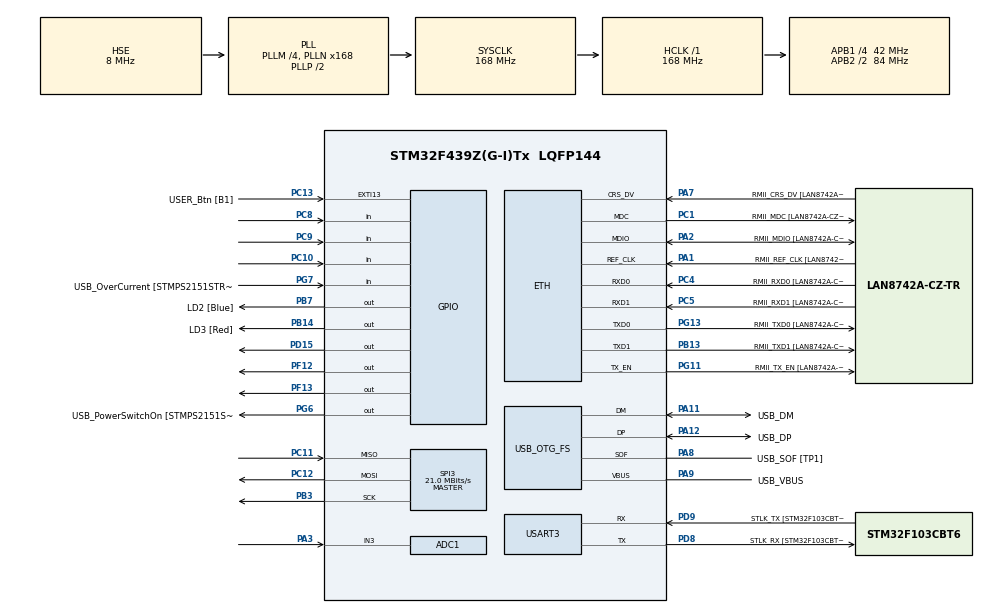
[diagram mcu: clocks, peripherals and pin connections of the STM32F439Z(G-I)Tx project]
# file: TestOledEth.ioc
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ADC1.Channel-1\#ChannelRegularConversion=ADC_CHANNEL_3
ADC1.NbrOfConversionFlag=1
ADC1.Rank-1\#ChannelRegularConversion=1
ADC1.SamplingTime-1\#ChannelRegularConversion=ADC_SAMPLETIME_3CYCLES
ADC1.master=1
ETH.MediaInterface=HAL_ETH_RMII_MODE
ETH.PHY_Name=LAN8742A_PHY_ADDRESS
ETH.PHY_Value=0
ETH.PhyAddress=0
FREERTOS.Tasks01=defaultTask,24,128,StartDefaultTask,Default,NULL,Dynamic,NULL,NULL
LWIP.BSP.number=1
LWIP.Version=v2.1.2_Cube
LWIP0.BSP.STBoard=false
LWIP0.BSP.api=BSP_COMPONENT_DRIVER
LWIP0.BSP.component=LAN8742
LWIP0.BSP.instance=LAN8742
LWIP0.BSP.name=Driver_PHY
LWIP0.BSP.semaphore=S_LAN8742
LWIP0.BSP.solution=LAN8742
Mcu.Family=STM32F4
Mcu.Name=STM32F439Z(G-I)Tx
Mcu.Package=LQFP144
NVIC.ETH_IRQn=true\:5\:0\:false\:false\:true\:true\:false\:true\:true
NVIC.PriorityGroup=NVIC_PRIORITYGROUP_4
NVIC.TIM6_DAC_IRQn=true\:15\:0\:false\:false\:true\:false\:false\:true\:true
NVIC.TimeBase=TIM6_DAC_IRQn
NVIC.TimeBaseIP=TIM6
PA1.GPIO_Label=RMII_REF_CLK [LAN8742A-CZ-TR_REFCLK0]
PA1.Mode=RMII
PA1.Signal=ETH_REF_CLK
PA10.GPIO_Label=USB_ID
PA10.Signal=USB_OTG_FS_ID
PA11.GPIO_Label=USB_DM
PA11.Mode=Device_Only
PA11.Signal=USB_OTG_FS_DM
PA12.GPIO_Label=USB_DP
PA12.Mode=Device_Only
PA12.Signal=USB_OTG_FS_DP
PA13.GPIO_Label=TMS
PA13.Mode=Serial_Wire
PA13.Signal=SYS_JTMS-SWDIO
PA14.GPIO_Label=TCK
PA14.Mode=Serial_Wire
PA14.Signal=SYS_JTCK-SWCLK
PA2.GPIO_Label=RMII_MDIO [LAN8742A-CZ-TR_MDIO]
PA2.Mode=RMII
PA2.Signal=ETH_MDIO
PA3.Signal=ADCx_IN3
PA7.GPIO_Label=RMII_CRS_DV [LAN8742A-CZ-TR_CRS_DV]
PA7.Mode=RMII
PA7.Signal=ETH_CRS_DV
PA8.GPIO_Label=USB_SOF [TP1]
PA8.Mode=Activate_SOF_FS
PA8.Signal=USB_OTG_FS_SOF
PA9.GPIO_Label=USB_VBUS
PA9.Mode=Activate_VBUS
PA9.Signal=USB_OTG_FS_VBUS
PB13.GPIO_Label=RMII_TXD1 [LAN8742A-CZ-TR_TXD1]
PB13.Mode=RMII
PB13.Signal=ETH_TXD1
PB14.GPIO_Label=LD3 [Red]
PB14.Signal=GPIO_Output
PB3.Mode=Full_Duplex_Master
PB3.Signal=SPI3_SCK
PB7.GPIO_Label=LD2 [Blue]
PB7.Signal=GPIO_Output
PC1.GPIO_Label=RMII_MDC [LAN8742A-CZ-TR_MDC]
PC1.Mode=RMII
PC1.Signal=ETH_MDC
PC10.GPIO_PuPd=GPIO_PULLUP
PC10.Signal=GPIO_Input
PC11.Mode=Full_Duplex_Master
PC11.Signal=SPI3_MISO
PC12.Mode=Full_Duplex_Master
PC12.Signal=SPI3_MOSI
PC13.GPIO_Label=USER_Btn [B1]
PC13.Signal=GPXTI13
PC14/OSC32_IN.Mode=LSE-External-Oscillator
PC14/OSC32_IN.Signal=RCC_OSC32_IN
PC15/OSC32_OUT.Mode=LSE-External-Oscillator
PC15/OSC32_OUT.Signal=RCC_OSC32_OUT
PC4.GPIO_Label=RMII_RXD0 [LAN8742A-CZ-TR_RXD0]
PC4.Mode=RMII
PC4.Signal=ETH_RXD0
PC5.GPIO_Label=RMII_RXD1 [LAN8742A-CZ-TR_RXD1]
PC5.Mode=RMII
PC5.Signal=ETH_RXD1
PC8.GPIO_PuPd=GPIO_PULLUP
PC8.Signal=GPIO_Input
PC9.GPIO_PuPd=GPIO_PULLUP
PC9.Signal=GPIO_Input
PD15.Signal=GPIO_Output
PD8.GPIO_Label=STLK_RX [STM32F103CBT6_PA3]
PD8.Mode=Asynchronous
PD8.Signal=USART3_TX
PD9.GPIO_Label=STLK_TX [STM32F103CBT6_PA2]
PD9.Mode=Asynchronous
PD9.Signal=USART3_RX
PF12.Signal=GPIO_Output
PF13.Signal=GPIO_Output
PG11.GPIO_Label=RMII_TX_EN [LAN8742A-CZ-TR_TXEN]
PG11.Mode=RMII
PG11.Signal=ETH_TX_EN
PG13.GPIO_Label=RMII_TXD0 [LAN8742A-CZ-TR_TXD0]
PG13.Mode=RMII
PG13.Signal=ETH_TXD0
PG6.GPIO_Label=USB_PowerSwitchOn [STMPS2151STR_EN]
PG6.Signal=GPIO_Output
PG7.GPIO_Label=USB_OverCurrent [STMPS2151STR_FAULT]
PG7.Signal=GPIO_Input
PH0/OSC_IN.GPIO_Label=MCO [STM32F103CBT6_PA8]
PH0/OSC_IN.Mode=HSE-External-Clock-Source
PH0/OSC_IN.Signal=RCC_OSC_IN
PH1/OSC_OUT.Mode=HSE-External-Clock-Source
PH1/OSC_OUT.Signal=RCC_OSC_OUT
ProjectManager.HeapSize=0x200
ProjectManager.StackSize=0x400
ProjectManager.TargetToolchain=CMake
RCC.48MHZClocksFreq_Value=48000000
RCC.AHBFreq_Value=168000000
RCC.APB1CLKDivider=RCC_HCLK_DIV4
RCC.APB1Freq_Value=42000000
RCC.APB1TimFreq_Value=84000000
RCC.APB2CLKDivider=RCC_HCLK_DIV2
RCC.APB2Freq_Value=84000000
RCC.APB2TimCLKDivider=2
RCC.APB2TimFreq_Value=168000000
RCC.CortexFreq_Value=168000000
RCC.HCLKFreq_Value=168000000
RCC.HSE_VALUE=8000000
RCC.HSI_VALUE=16000000
RCC.PLLM=4
RCC.PLLMUL=RCC_PLL_MUL9
RCC.PLLN=168
RCC.PLLQ=7
RCC.PRESCALERUSB=RCC_USBCLKSOURCE_PLL_DIV1_5
RCC.SYSCLKFreq_VALUE=168000000
RCC.SYSCLKSource=RCC_SYSCLKSOURCE_PLLCLK
RCC.SYSCLKSourceVirtual=RCC_SYSCLKSOURCE_PLLCLK
RCC.USBFreq_Value=48000000
RCC.VCOOutputFreq_Value=336000000
SH.ADCx_IN3.0=ADC1_IN3,IN3
SPI3.CalculateBaudRate=21.0 MBits/s
SPI3.Direction=SPI_DIRECTION_2LINES
SPI3.Mode=SPI_MODE_MASTER
SPI3.VirtualType=VM_MASTER
TIM2.Prescaler=83
USART3.VirtualMode=VM_ASYNC
USB_OTG_FS.VirtualMode=Device_Only
VP_FREERTOS_VS_CMSIS_V2.Mode=CMSIS_V2
VP_LWIP_VS_Enabled.Mode=Enabled
VP_MBEDTLS_VS_MBEDTLS.Mode=Enabled
VP_RTC_VS_RTC_Activate.Mode=RTC_Enabled
VP_SYS_VS_tim6.Mode=TIM6
VP_TIM2_VS_ClockSourceINT.Mode=Internal
board=NUCLEO-F439ZI

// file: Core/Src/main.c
/* USER CODE BEGIN Header */
/**
  ******************************************************************************
  * @file           : main.c
  * @brief          : Main program body
  ******************************************************************************
  * @attention
  *
  * Copyright (c) 2026 STMicroelectronics.
  * All rights reserved.
  *
  * This software is licensed under terms that can be found in the LICENSE file
  * in the root directory of this software component.
  * If no LICENSE file comes with this software, it is provided AS-IS.
  *
  ******************************************************************************
  */
/* USER CODE END Header */
#include "main.h"
#include "cmsis_os.h"
#include "mbedtls.h"

/* USER CODE BEGIN Includes */
#include "appMain.h"
/* USER CODE END Includes */

ADC_HandleTypeDef hadc1;

RTC_HandleTypeDef hrtc;

SPI_HandleTypeDef hspi3;

TIM_HandleTypeDef htim2;

UART_HandleTypeDef huart3;

PCD_HandleTypeDef hpcd_USB_OTG_FS;

/* Definitions for defaultTask */
osThreadId_t defaultTaskHandle;
const osThreadAttr_t defaultTask_attributes = {
  .name = "defaultTask",
  .stack_size = 2048,
  .priority = (osPriority_t) osPriorityNormal,
};

void SystemClock_Config(void);
static void MX_GPIO_Init(void);
static void MX_TIM2_Init(void);
static void MX_USART3_UART_Init(void);
static void MX_USB_OTG_FS_PCD_Init(void);
static void MX_ADC1_Init(void);
static void MX_SPI3_Init(void);
static void MX_RTC_Init(void);
void StartDefaultTask(void *argument);

int main(void)
{

  /* MCU Configuration--------------------------------------------------------*/

  /* Reset of all peripherals, Initializes the Flash interface and the Systick. */
  HAL_Init();

  /* Configure the system clock */
  SystemClock_Config();

  /* Initialize all configured peripherals */
  MX_GPIO_Init();
  MX_TIM2_Init();
  MX_USART3_UART_Init();
  MX_USB_OTG_FS_PCD_Init();
  MX_ADC1_Init();
  MX_SPI3_Init();
  MX_RTC_Init();
  /* Call PreOsInit function */
  MX_MBEDTLS_Init();

  /* Init scheduler */
  osKernelInitialize();

  /* Create the thread(s) */
  /* creation of defaultTask */
  defaultTaskHandle = osThreadNew(StartDefaultTask, NULL, &defaultTask_attributes);

  /* Start scheduler */
  osKernelStart();

  /* We should never get here as control is now taken by the scheduler */

  /* Infinite loop */
  while (1)
  {

  }
}

void SystemClock_Config(void)
{
  RCC_OscInitTypeDef RCC_OscInitStruct = {0};
  RCC_ClkInitTypeDef RCC_ClkInitStruct = {0};

  /** Configure the main internal regulator output voltage
  */
  __HAL_RCC_PWR_CLK_ENABLE();
  __HAL_PWR_VOLTAGESCALING_CONFIG(PWR_REGULATOR_VOLTAGE_SCALE1);

  /** Initializes the RCC Oscillators according to the specified parameters
  * in the RCC_OscInitTypeDef structure.
  */
  RCC_OscInitStruct.OscillatorType = RCC_OSCILLATORTYPE_LSI|RCC_OSCILLATORTYPE_HSE;
  RCC_OscInitStruct.HSEState = RCC_HSE_BYPASS;
  RCC_OscInitStruct.LSIState = RCC_LSI_ON;
  RCC_OscInitStruct.PLL.PLLState = RCC_PLL_ON;
  RCC_OscInitStruct.PLL.PLLSource = RCC_PLLSOURCE_HSE;
  RCC_OscInitStruct.PLL.PLLM = 4;
  RCC_OscInitStruct.PLL.PLLN = 168;
  RCC_OscInitStruct.PLL.PLLP = RCC_PLLP_DIV2;
  RCC_OscInitStruct.PLL.PLLQ = 7;
  if (HAL_RCC_OscConfig(&RCC_OscInitStruct) != HAL_OK)
  {
    Error_Handler();
  }

  /** Initializes the CPU, AHB and APB buses clocks
  */
  RCC_ClkInitStruct.ClockType = RCC_CLOCKTYPE_HCLK|RCC_CLOCKTYPE_SYSCLK
                              |RCC_CLOCKTYPE_PCLK1|RCC_CLOCKTYPE_PCLK2;
  RCC_ClkInitStruct.SYSCLKSource = RCC_SYSCLKSOURCE_PLLCLK;
  RCC_ClkInitStruct.AHBCLKDivider = RCC_SYSCLK_DIV1;
  RCC_ClkInitStruct.APB1CLKDivider = RCC_HCLK_DIV4;
  RCC_ClkInitStruct.APB2CLKDivider = RCC_HCLK_DIV2;

  if (HAL_RCC_ClockConfig(&RCC_ClkInitStruct, FLASH_LATENCY_5) != HAL_OK)
  {
    Error_Handler();
  }
}

static void MX_ADC1_Init(void)
{

  ADC_ChannelConfTypeDef sConfig = {0};

  /** Configure the global features of the ADC (Clock, Resolution, Data Alignment and number of conversion)
  */
  hadc1.Instance = ADC1;
  hadc1.Init.ClockPrescaler = ADC_CLOCK_SYNC_PCLK_DIV4;
  hadc1.Init.Resolution = ADC_RESOLUTION_12B;
  hadc1.Init.ScanConvMode = DISABLE;
  hadc1.Init.ContinuousConvMode = DISABLE;
  hadc1.Init.DiscontinuousConvMode = DISABLE;
  hadc1.Init.ExternalTrigConvEdge = ADC_EXTERNALTRIGCONVEDGE_NONE;
  hadc1.Init.ExternalTrigConv = ADC_SOFTWARE_START;
  hadc1.Init.DataAlign = ADC_DATAALIGN_RIGHT;
  hadc1.Init.NbrOfConversion = 1;
  hadc1.Init.DMAContinuousRequests = DISABLE;
  hadc1.Init.EOCSelection = ADC_EOC_SINGLE_CONV;
  if (HAL_ADC_Init(&hadc1) != HAL_OK)
  {
    Error_Handler();
  }

  /** Configure for the selected ADC regular channel its corresponding rank in the sequencer and its sample time.
  */
  sConfig.Channel = ADC_CHANNEL_3;
  sConfig.Rank = 1;
  sConfig.SamplingTime = ADC_SAMPLETIME_3CYCLES;
  if (HAL_ADC_ConfigChannel(&hadc1, &sConfig) != HAL_OK)
  {
    Error_Handler();
  }

}

static void MX_RTC_Init(void)
{

  /** Initialize RTC Only
  */
  hrtc.Instance = RTC;
  hrtc.Init.HourFormat = RTC_HOURFORMAT_24;
  hrtc.Init.AsynchPrediv = 127;
  hrtc.Init.SynchPrediv = 255;
  hrtc.Init.OutPut = RTC_OUTPUT_DISABLE;
  hrtc.Init.OutPutPolarity = RTC_OUTPUT_POLARITY_HIGH;
  hrtc.Init.OutPutType = RTC_OUTPUT_TYPE_OPENDRAIN;
  if (HAL_RTC_Init(&hrtc) != HAL_OK)
  {
    Error_Handler();
  }

}

static void MX_SPI3_Init(void)
{

  /* SPI3 parameter configuration*/
  hspi3.Instance = SPI3;
  hspi3.Init.Mode = SPI_MODE_MASTER;
  hspi3.Init.Direction = SPI_DIRECTION_2LINES;
  hspi3.Init.DataSize = SPI_DATASIZE_8BIT;
  hspi3.Init.CLKPolarity = SPI_POLARITY_LOW;
  hspi3.Init.CLKPhase = SPI_PHASE_1EDGE;
  hspi3.Init.NSS = SPI_NSS_SOFT;
  hspi3.Init.BaudRatePrescaler = SPI_BAUDRATEPRESCALER_4;
  hspi3.Init.FirstBit = SPI_FIRSTBIT_MSB;
  hspi3.Init.TIMode = SPI_TIMODE_DISABLE;
  hspi3.Init.CRCCalculation = SPI_CRCCALCULATION_DISABLE;
  hspi3.Init.CRCPolynomial = 10;
  if (HAL_SPI_Init(&hspi3) != HAL_OK)
  {
    Error_Handler();
  }

}

static void MX_TIM2_Init(void)
{

  TIM_ClockConfigTypeDef sClockSourceConfig = {0};
  TIM_MasterConfigTypeDef sMasterConfig = {0};

  htim2.Instance = TIM2;
  htim2.Init.Prescaler = 83;
  htim2.Init.CounterMode = TIM_COUNTERMODE_UP;
  htim2.Init.Period = 4294967295;
  htim2.Init.ClockDivision = TIM_CLOCKDIVISION_DIV1;
  htim2.Init.AutoReloadPreload = TIM_AUTORELOAD_PRELOAD_DISABLE;
  if (HAL_TIM_Base_Init(&htim2) != HAL_OK)
  {
    Error_Handler();
  }
  sClockSourceConfig.ClockSource = TIM_CLOCKSOURCE_INTERNAL;
  if (HAL_TIM_ConfigClockSource(&htim2, &sClockSourceConfig) != HAL_OK)
  {
    Error_Handler();
  }
  sMasterConfig.MasterOutputTrigger = TIM_TRGO_RESET;
  sMasterConfig.MasterSlaveMode = TIM_MASTERSLAVEMODE_DISABLE;
  if (HAL_TIMEx_MasterConfigSynchronization(&htim2, &sMasterConfig) != HAL_OK)
  {
    Error_Handler();
  }
  /* USER CODE BEGIN TIM2_Init 2 */
  HAL_TIM_Base_Start(&htim2);
  /* USER CODE END TIM2_Init 2 */

}

static void MX_USART3_UART_Init(void)
{

  huart3.Instance = USART3;
  huart3.Init.BaudRate = 115200;
  huart3.Init.WordLength = UART_WORDLENGTH_8B;
  huart3.Init.StopBits = UART_STOPBITS_1;
  huart3.Init.Parity = UART_PARITY_NONE;
  huart3.Init.Mode = UART_MODE_TX_RX;
  huart3.Init.HwFlowCtl = UART_HWCONTROL_NONE;
  huart3.Init.OverSampling = UART_OVERSAMPLING_16;
  if (HAL_UART_Init(&huart3) != HAL_OK)
  {
    Error_Handler();
  }

}

static void MX_USB_OTG_FS_PCD_Init(void)
{

  hpcd_USB_OTG_FS.Instance = USB_OTG_FS;
  hpcd_USB_OTG_FS.Init.dev_endpoints = 4;
  hpcd_USB_OTG_FS.Init.speed = PCD_SPEED_FULL;
  hpcd_USB_OTG_FS.Init.dma_enable = DISABLE;
  hpcd_USB_OTG_FS.Init.phy_itface = PCD_PHY_EMBEDDED;
  hpcd_USB_OTG_FS.Init.Sof_enable = ENABLE;
  hpcd_USB_OTG_FS.Init.low_power_enable = DISABLE;
  hpcd_USB_OTG_FS.Init.lpm_enable = DISABLE;
  hpcd_USB_OTG_FS.Init.vbus_sensing_enable = ENABLE;
  hpcd_USB_OTG_FS.Init.use_dedicated_ep1 = DISABLE;
  if (HAL_PCD_Init(&hpcd_USB_OTG_FS) != HAL_OK)
  {
    Error_Handler();
  }

}

static void MX_GPIO_Init(void)
{
  GPIO_InitTypeDef GPIO_InitStruct = {0};

  /* GPIO Ports Clock Enable */
  __HAL_RCC_GPIOC_CLK_ENABLE();
  __HAL_RCC_GPIOH_CLK_ENABLE();
  __HAL_RCC_GPIOA_CLK_ENABLE();
  __HAL_RCC_GPIOF_CLK_ENABLE();
  __HAL_RCC_GPIOB_CLK_ENABLE();
  __HAL_RCC_GPIOD_CLK_ENABLE();
  __HAL_RCC_GPIOG_CLK_ENABLE();

  /*Configure GPIO pin Output Level */
  HAL_GPIO_WritePin(GPIOF, GPIO_PIN_12|GPIO_PIN_13, GPIO_PIN_RESET);

  /*Configure GPIO pin Output Level */
  HAL_GPIO_WritePin(GPIOB, LD3_Pin|LD2_Pin, GPIO_PIN_RESET);

  /*Configure GPIO pin Output Level */
  HAL_GPIO_WritePin(GPIOD, GPIO_PIN_15, GPIO_PIN_RESET);

  /*Configure GPIO pin Output Level */
  HAL_GPIO_WritePin(USB_PowerSwitchOn_GPIO_Port, USB_PowerSwitchOn_Pin, GPIO_PIN_RESET);

  /*Configure GPIO pin : USER_Btn_Pin */
  GPIO_InitStruct.Pin = USER_Btn_Pin;
  GPIO_InitStruct.Mode = GPIO_MODE_IT_RISING;
  GPIO_InitStruct.Pull = GPIO_NOPULL;
  HAL_GPIO_Init(USER_Btn_GPIO_Port, &GPIO_InitStruct);

  /*Configure GPIO pins : PF12 PF13 */
  GPIO_InitStruct.Pin = GPIO_PIN_12|GPIO_PIN_13;
  GPIO_InitStruct.Mode = GPIO_MODE_OUTPUT_PP;
  GPIO_InitStruct.Pull = GPIO_NOPULL;
  GPIO_InitStruct.Speed = GPIO_SPEED_FREQ_LOW;
  HAL_GPIO_Init(GPIOF, &GPIO_InitStruct);

  /*Configure GPIO pins : LD3_Pin LD2_Pin */
  GPIO_InitStruct.Pin = LD3_Pin|LD2_Pin;
  GPIO_InitStruct.Mode = GPIO_MODE_OUTPUT_PP;
  GPIO_InitStruct.Pull = GPIO_NOPULL;
  GPIO_InitStruct.Speed = GPIO_SPEED_FREQ_LOW;
  HAL_GPIO_Init(GPIOB, &GPIO_InitStruct);

  /*Configure GPIO pin : PD15 */
  GPIO_InitStruct.Pin = GPIO_PIN_15;
  GPIO_InitStruct.Mode = GPIO_MODE_OUTPUT_PP;
  GPIO_InitStruct.Pull = GPIO_NOPULL;
  GPIO_InitStruct.Speed = GPIO_SPEED_FREQ_LOW;
  HAL_GPIO_Init(GPIOD, &GPIO_InitStruct);

  /*Configure GPIO pin : USB_PowerSwitchOn_Pin */
  GPIO_InitStruct.Pin = USB_PowerSwitchOn_Pin;
  GPIO_InitStruct.Mode = GPIO_MODE_OUTPUT_PP;
  GPIO_InitStruct.Pull = GPIO_NOPULL;
  GPIO_InitStruct.Speed = GPIO_SPEED_FREQ_LOW;
  HAL_GPIO_Init(USB_PowerSwitchOn_GPIO_Port, &GPIO_InitStruct);

  /*Configure GPIO pin : USB_OverCurrent_Pin */
  GPIO_InitStruct.Pin = USB_OverCurrent_Pin;
  GPIO_InitStruct.Mode = GPIO_MODE_INPUT;
  GPIO_InitStruct.Pull = GPIO_NOPULL;
  HAL_GPIO_Init(USB_OverCurrent_GPIO_Port, &GPIO_InitStruct);

  /*Configure GPIO pins : PC8 PC9 PC10 */
  GPIO_InitStruct.Pin = GPIO_PIN_8|GPIO_PIN_9|GPIO_PIN_10;
  GPIO_InitStruct.Mode = GPIO_MODE_INPUT;
  GPIO_InitStruct.Pull = GPIO_PULLUP;
  HAL_GPIO_Init(GPIOC, &GPIO_InitStruct);

}

void StartDefaultTask(void *argument)
{
  /* USER CODE BEGIN 5 */
    runMenuApp();
  /* USER CODE END 5 */
}

void HAL_TIM_PeriodElapsedCallback(TIM_HandleTypeDef *htim)
{
  if (htim->Instance == TIM6)
  {
    HAL_IncTick();
  }
}

void Error_Handler(void)
{
  __disable_irq();
  while (1)
  {
  }
}
